AUTOSAR XML (schema 00044)
package /ComponentTypes
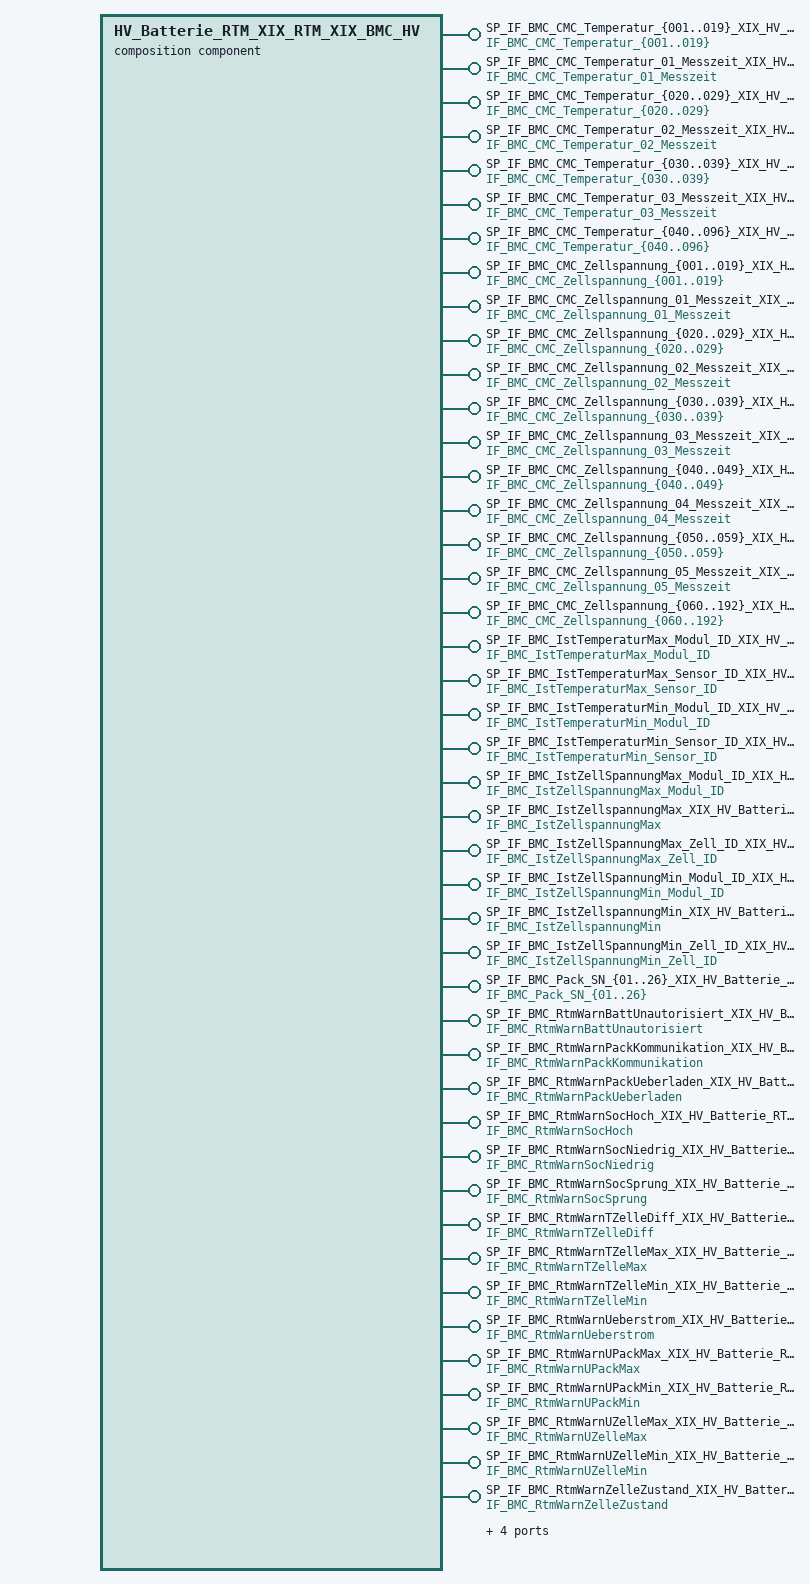
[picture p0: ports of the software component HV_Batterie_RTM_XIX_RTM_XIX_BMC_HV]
  composition sw component type HV_Batterie_RTM_XIX_RTM_XIX_BMC_HV
    351 x provide port:
      SP_IF_BMC_CMC_Temperatur_{001..019}_XIX_HV_Batterie_RTM_XIX_RTM_XIX_BMC_HV: nonqueued-sender-com-spec=DE_BMC_CMC_Temperatur_{001..019}, provided-interface=IF_BMC_CMC_Temperatur_{001..019}
      SP_IF_BMC_CMC_Temperatur_01_Messzeit_XIX_HV_Batterie_RTM_XIX_RTM_XIX_BMC_HV: nonqueued-sender-com-spec=DE_BMC_CMC_Temperatur_01_Messzeit, provided-interface=IF_BMC_CMC_Temperatur_01_Messzeit
      SP_IF_BMC_CMC_Temperatur_{020..029}_XIX_HV_Batterie_RTM_XIX_RTM_XIX_BMC_HV: nonqueued-sender-com-spec=DE_BMC_CMC_Temperatur_{020..029}, provided-interface=IF_BMC_CMC_Temperatur_{020..029}
      SP_IF_BMC_CMC_Temperatur_02_Messzeit_XIX_HV_Batterie_RTM_XIX_RTM_XIX_BMC_HV: nonqueued-sender-com-spec=DE_BMC_CMC_Temperatur_02_Messzeit, provided-interface=IF_BMC_CMC_Temperatur_02_Messzeit
      SP_IF_BMC_CMC_Temperatur_{030..039}_XIX_HV_Batterie_RTM_XIX_RTM_XIX_BMC_HV: nonqueued-sender-com-spec=DE_BMC_CMC_Temperatur_{030..039}, provided-interface=IF_BMC_CMC_Temperatur_{030..039}
      SP_IF_BMC_CMC_Temperatur_03_Messzeit_XIX_HV_Batterie_RTM_XIX_RTM_XIX_BMC_HV: nonqueued-sender-com-spec=DE_BMC_CMC_Temperatur_03_Messzeit, provided-interface=IF_BMC_CMC_Temperatur_03_Messzeit
      SP_IF_BMC_CMC_Temperatur_{040..096}_XIX_HV_Batterie_RTM_XIX_RTM_XIX_BMC_HV: nonqueued-sender-com-spec=DE_BMC_CMC_Temperatur_{040..096}, provided-interface=IF_BMC_CMC_Temperatur_{040..096}
      SP_IF_BMC_CMC_Zellspannung_{001..019}_XIX_HV_Batterie_RTM_XIX_RTM_XIX_BMC_HV: nonqueued-sender-com-spec=DE_BMC_CMC_Zellspannung_{001..019}, provided-interface=IF_BMC_CMC_Zellspannung_{001..019}
      SP_IF_BMC_CMC_Zellspannung_01_Messzeit_XIX_HV_Batterie_RTM_XIX_RTM_XIX_BMC_HV: nonqueued-sender-com-spec=DE_BMC_CMC_Zellspannung_01_Messzeit, provided-interface=IF_BMC_CMC_Zellspannung_01_Messzeit
      SP_IF_BMC_CMC_Zellspannung_{020..029}_XIX_HV_Batterie_RTM_XIX_RTM_XIX_BMC_HV: nonqueued-sender-com-spec=DE_BMC_CMC_Zellspannung_{020..029}, provided-interface=IF_BMC_CMC_Zellspannung_{020..029}
      SP_IF_BMC_CMC_Zellspannung_02_Messzeit_XIX_HV_Batterie_RTM_XIX_RTM_XIX_BMC_HV: nonqueued-sender-com-spec=DE_BMC_CMC_Zellspannung_02_Messzeit, provided-interface=IF_BMC_CMC_Zellspannung_02_Messzeit
      SP_IF_BMC_CMC_Zellspannung_{030..039}_XIX_HV_Batterie_RTM_XIX_RTM_XIX_BMC_HV: nonqueued-sender-com-spec=DE_BMC_CMC_Zellspannung_{030..039}, provided-interface=IF_BMC_CMC_Zellspannung_{030..039}
      SP_IF_BMC_CMC_Zellspannung_03_Messzeit_XIX_HV_Batterie_RTM_XIX_RTM_XIX_BMC_HV: nonqueued-sender-com-spec=DE_BMC_CMC_Zellspannung_03_Messzeit, provided-interface=IF_BMC_CMC_Zellspannung_03_Messzeit
      SP_IF_BMC_CMC_Zellspannung_{040..049}_XIX_HV_Batterie_RTM_XIX_RTM_XIX_BMC_HV: nonqueued-sender-com-spec=DE_BMC_CMC_Zellspannung_{040..049}, provided-interface=IF_BMC_CMC_Zellspannung_{040..049}
      SP_IF_BMC_CMC_Zellspannung_04_Messzeit_XIX_HV_Batterie_RTM_XIX_RTM_XIX_BMC_HV: nonqueued-sender-com-spec=DE_BMC_CMC_Zellspannung_04_Messzeit, provided-interface=IF_BMC_CMC_Zellspannung_04_Messzeit
      SP_IF_BMC_CMC_Zellspannung_{050..059}_XIX_HV_Batterie_RTM_XIX_RTM_XIX_BMC_HV: nonqueued-sender-com-spec=DE_BMC_CMC_Zellspannung_{050..059}, provided-interface=IF_BMC_CMC_Zellspannung_{050..059}
      SP_IF_BMC_CMC_Zellspannung_05_Messzeit_XIX_HV_Batterie_RTM_XIX_RTM_XIX_BMC_HV: nonqueued-sender-com-spec=DE_BMC_CMC_Zellspannung_05_Messzeit, provided-interface=IF_BMC_CMC_Zellspannung_05_Messzeit
      SP_IF_BMC_CMC_Zellspannung_{060..192}_XIX_HV_Batterie_RTM_XIX_RTM_XIX_BMC_HV: nonqueued-sender-com-spec=DE_BMC_CMC_Zellspannung_{060..192}, provided-interface=IF_BMC_CMC_Zellspannung_{060..192}
      SP_IF_BMC_IstTemperaturMax_Modul_ID_XIX_HV_Batterie_RTM_XIX_RTM_XIX_BMC_HV: nonqueued-sender-com-spec=DE_BMC_IstTemperaturMax_Modul_ID, provided-interface=IF_BMC_IstTemperaturMax_Modul_ID
      SP_IF_BMC_IstTemperaturMax_Sensor_ID_XIX_HV_Batterie_RTM_XIX_RTM_XIX_BMC_HV: nonqueued-sender-com-spec=DE_BMC_IstTemperaturMax_Sensor_ID, provided-interface=IF_BMC_IstTemperaturMax_Sensor_ID
      SP_IF_BMC_IstTemperaturMin_Modul_ID_XIX_HV_Batterie_RTM_XIX_RTM_XIX_BMC_HV: nonqueued-sender-com-spec=DE_BMC_IstTemperaturMin_Modul_ID, provided-interface=IF_BMC_IstTemperaturMin_Modul_ID
      SP_IF_BMC_IstTemperaturMin_Sensor_ID_XIX_HV_Batterie_RTM_XIX_RTM_XIX_BMC_HV: nonqueued-sender-com-spec=DE_BMC_IstTemperaturMin_Sensor_ID, provided-interface=IF_BMC_IstTemperaturMin_Sensor_ID
      SP_IF_BMC_IstZellSpannungMax_Modul_ID_XIX_HV_Batterie_RTM_XIX_RTM_XIX_BMC_HV: nonqueued-sender-com-spec=DE_BMC_IstZellSpannungMax_Modul_ID, provided-interface=IF_BMC_IstZellSpannungMax_Modul_ID
      SP_IF_BMC_IstZellspannungMax_XIX_HV_Batterie_RTM_XIX_RTM_XIX_BMC_HV: nonqueued-sender-com-spec=DE_BMC_IstZellspannungMax, provided-interface=IF_BMC_IstZellspannungMax
      SP_IF_BMC_IstZellSpannungMax_Zell_ID_XIX_HV_Batterie_RTM_XIX_RTM_XIX_BMC_HV: nonqueued-sender-com-spec=DE_BMC_IstZellSpannungMax_Zell_ID, provided-interface=IF_BMC_IstZellSpannungMax_Zell_ID
      SP_IF_BMC_IstZellSpannungMin_Modul_ID_XIX_HV_Batterie_RTM_XIX_RTM_XIX_BMC_HV: nonqueued-sender-com-spec=DE_BMC_IstZellSpannungMin_Modul_ID, provided-interface=IF_BMC_IstZellSpannungMin_Modul_ID
      SP_IF_BMC_IstZellspannungMin_XIX_HV_Batterie_RTM_XIX_RTM_XIX_BMC_HV: nonqueued-sender-com-spec=DE_BMC_IstZellspannungMin, provided-interface=IF_BMC_IstZellspannungMin
      SP_IF_BMC_IstZellSpannungMin_Zell_ID_XIX_HV_Batterie_RTM_XIX_RTM_XIX_BMC_HV: nonqueued-sender-com-spec=DE_BMC_IstZellSpannungMin_Zell_ID, provided-interface=IF_BMC_IstZellSpannungMin_Zell_ID
      SP_IF_BMC_Pack_SN_{01..26}_XIX_HV_Batterie_RTM_XIX_RTM_XIX_BMC_HV: nonqueued-sender-com-spec=DE_BMC_Pack_SN_{01..26}, provided-interface=IF_BMC_Pack_SN_{01..26}
      SP_IF_BMC_RtmWarnBattUnautorisiert_XIX_HV_Batterie_RTM_XIX_RTM_XIX_BMC_HV: nonqueued-sender-com-spec=DE_BMC_RtmWarnBattUnautorisiert, provided-interface=IF_BMC_RtmWarnBattUnautorisiert
      SP_IF_BMC_RtmWarnPackKommunikation_XIX_HV_Batterie_RTM_XIX_RTM_XIX_BMC_HV: nonqueued-sender-com-spec=DE_BMC_RtmWarnPackKommunikation, provided-interface=IF_BMC_RtmWarnPackKommunikation
      SP_IF_BMC_RtmWarnPackUeberladen_XIX_HV_Batterie_RTM_XIX_RTM_XIX_BMC_HV: nonqueued-sender-com-spec=DE_BMC_RtmWarnPackUeberladen, provided-interface=IF_BMC_RtmWarnPackUeberladen
      SP_IF_BMC_RtmWarnSocHoch_XIX_HV_Batterie_RTM_XIX_RTM_XIX_BMC_HV: nonqueued-sender-com-spec=DE_BMC_RtmWarnSocHoch, provided-interface=IF_BMC_RtmWarnSocHoch
      SP_IF_BMC_RtmWarnSocNiedrig_XIX_HV_Batterie_RTM_XIX_RTM_XIX_BMC_HV: nonqueued-sender-com-spec=DE_BMC_RtmWarnSocNiedrig, provided-interface=IF_BMC_RtmWarnSocNiedrig
      SP_IF_BMC_RtmWarnSocSprung_XIX_HV_Batterie_RTM_XIX_RTM_XIX_BMC_HV: nonqueued-sender-com-spec=DE_BMC_RtmWarnSocSprung, provided-interface=IF_BMC_RtmWarnSocSprung
      SP_IF_BMC_RtmWarnTZelleDiff_XIX_HV_Batterie_RTM_XIX_RTM_XIX_BMC_HV: nonqueued-sender-com-spec=DE_BMC_RtmWarnTZelleDiff, provided-interface=IF_BMC_RtmWarnTZelleDiff
      SP_IF_BMC_RtmWarnTZelleMax_XIX_HV_Batterie_RTM_XIX_RTM_XIX_BMC_HV: nonqueued-sender-com-spec=DE_BMC_RtmWarnTZelleMax, provided-interface=IF_BMC_RtmWarnTZelleMax
      SP_IF_BMC_RtmWarnTZelleMin_XIX_HV_Batterie_RTM_XIX_RTM_XIX_BMC_HV: nonqueued-sender-com-spec=DE_BMC_RtmWarnTZelleMin, provided-interface=IF_BMC_RtmWarnTZelleMin
      SP_IF_BMC_RtmWarnUeberstrom_XIX_HV_Batterie_RTM_XIX_RTM_XIX_BMC_HV: nonqueued-sender-com-spec=DE_BMC_RtmWarnUeberstrom, provided-interface=IF_BMC_RtmWarnUeberstrom
      SP_IF_BMC_RtmWarnUPackMax_XIX_HV_Batterie_RTM_XIX_RTM_XIX_BMC_HV: nonqueued-sender-com-spec=DE_BMC_RtmWarnUPackMax, provided-interface=IF_BMC_RtmWarnUPackMax
      SP_IF_BMC_RtmWarnUPackMin_XIX_HV_Batterie_RTM_XIX_RTM_XIX_BMC_HV: nonqueued-sender-com-spec=DE_BMC_RtmWarnUPackMin, provided-interface=IF_BMC_RtmWarnUPackMin
      SP_IF_BMC_RtmWarnUZelleMax_XIX_HV_Batterie_RTM_XIX_RTM_XIX_BMC_HV: nonqueued-sender-com-spec=DE_BMC_RtmWarnUZelleMax, provided-interface=IF_BMC_RtmWarnUZelleMax
      SP_IF_BMC_RtmWarnUZelleMin_XIX_HV_Batterie_RTM_XIX_RTM_XIX_BMC_HV: nonqueued-sender-com-spec=DE_BMC_RtmWarnUZelleMin, provided-interface=IF_BMC_RtmWarnUZelleMin
      SP_IF_BMC_RtmWarnZelleZustand_XIX_HV_Batterie_RTM_XIX_RTM_XIX_BMC_HV: nonqueued-sender-com-spec=DE_BMC_RtmWarnZelleZustand, provided-interface=IF_BMC_RtmWarnZelleZustand
      SP_IF_BMC_Spannung_Messzeit_XIX_HV_Batterie_RTM_XIX_RTM_XIX_BMC_HV: nonqueued-sender-com-spec=DE_BMC_Spannung_Messzeit, provided-interface=IF_BMC_Spannung_Messzeit
      SP_IF_BMC_Strom_Messzeit_XIX_HV_Batterie_RTM_XIX_RTM_XIX_BMC_HV: nonqueued-sender-com-spec=DE_BMC_Strom_Messzeit, provided-interface=IF_BMC_Strom_Messzeit
      SP_IF_BMC_Temperatur_hoechste_XIX_HV_Batterie_RTM_XIX_RTM_XIX_BMC_HV: nonqueued-sender-com-spec=DE_BMC_Temperatur_hoechste, provided-interface=IF_BMC_Temperatur_hoechste
      SP_IF_BMC_Temperatur_niedrigste_XIX_HV_Batterie_RTM_XIX_RTM_XIX_BMC_HV: nonqueued-sender-com-spec=DE_BMC_Temperatur_niedrigste, provided-interface=IF_BMC_Temperatur_niedrigste
